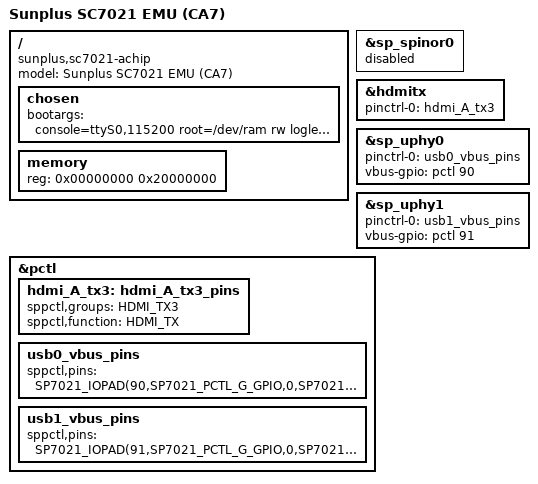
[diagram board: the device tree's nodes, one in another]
/dts-v1/;

#include "pentagram-sp7021-achip.dtsi"

#include <dt-bindings/interrupt-controller/arm-gic.h>

/ {
	model = "Sunplus SC7021 EMU (CA7)";
	compatible = "sunplus,sc7021-achip";

	chosen {
		bootargs = "console=ttyS0,115200 root=/dev/ram rw loglevel=8 earlyprintk";
	};

	memory {
		reg = <0x00000000 0x20000000>; /* 512MB */
	};
};

&sp_spinor0 {  status = "disabled";  };

&hdmitx {
 pinctrl-names = "default";
 pinctrl-0 = <&hdmi_A_tx3>;
};

&sp_uphy0 {
  pinctrl-names = "default";
  pinctrl-0 = <&usb0_vbus_pins>;
  vbus-gpio = <&pctl 90 GPIO_ACTIVE_HIGH>;
};

&sp_uphy1 {
  pinctrl-names = "default";
  pinctrl-0 = <&usb1_vbus_pins>;
  vbus-gpio = <&pctl 91 GPIO_ACTIVE_HIGH>;
};

&pctl {
 hdmi_A_tx3: hdmi_A_tx3_pins {
    sppctl,groups = "HDMI_TX3";
    sppctl,function = "HDMI_TX";
 };

 usb0_vbus_pins: usb0_vbus_pins {
	sppctl,pins = <
	  SP7021_IOPAD(90,SP7021_PCTL_G_GPIO,0,SP7021_PCTL_L_OUT)
	>;
 };
 usb1_vbus_pins: usb1_vbus_pins {
    sppctl,pins = <
	  SP7021_IOPAD(91,SP7021_PCTL_G_GPIO,0,SP7021_PCTL_L_OUT)
	>;
 };

};
